# MK22FA12 register map
Vendor: Freescale Semiconductor, Inc.; Series: Kinetis_K; File version: 1.6
CPU: CM4 r0p1, little endian, no MPU, FPU, VTOR, 4 interrupt priority bits
Registers are 32-bit, read-write, reset 0x0 unless marked. A register's access mark holds for its fields unless they carry their own. Offsets are from the block's base; [hi:lo] are bit positions.

## RTC — Secure Real Time Clock
Base 0x4003D000; register names take the prefix RTC_
0x00 TSR — RTC Time Seconds Register
  [31:0] TSR — Time Seconds Register
0x04 TPR — RTC Time Prescaler Register
  [15:0] TPR — Time Prescaler Register
0x08 TAR — RTC Time Alarm Register
  [31:0] TAR — Time Alarm Register
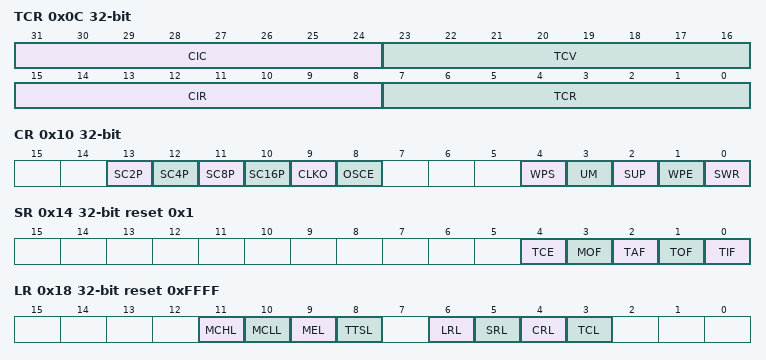
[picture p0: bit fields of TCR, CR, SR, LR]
0x0C TCR — RTC Time Compensation Register
  [31:24] CIC ro — Compensation Interval Counter
  [23:16] TCV ro — Time Compensation Value
  [15:8] CIR — Compensation Interval Register
  [7:0] TCR — Time Compensation Register
    128=Time Prescaler Register overflows every 32896 clock cycles; 255=Time Prescaler Register overflows every 32769 clock cycles; 0=Time Prescaler Register overflows every 32768 clock cycles; 1=Time Prescaler Register overflows every 32767 clock cycles; 127=Time Prescaler Register overflows every 32641 clock cycles
0x10 CR — RTC Control Register
  [13] SC2P — Oscillator 2pF Load Configure
    0=Disable the load; 1=Enable the additional load
  [12] SC4P — Oscillator 4pF Load Configure
    0=Disable the load; 1=Enable the additional load
  [11] SC8P — Oscillator 8pF Load Configure
    0=Disable the load; 1=Enable the additional load
  [10] SC16P — Oscillator 16pF Load Configure
    0=Disable the load; 1=Enable the additional load
  [9] CLKO — Clock Output
    0=The 32 kHz clock is output to other peripherals; 1=The 32 kHz clock is not output to other peripherals
  [8] OSCE — Oscillator Enable
    0=32.768 kHz oscillator is disabled; 1=32.768 kHz oscillator is enabled. After setting this bit, wait the oscillator startup time before enabling the time counter to allow the 32.768 kHz clock time to stabilize.
  [4] WPS — Wakeup Pin Select
    0=Wakeup pin asserts (active low, open drain) if the RTC interrupt asserts or the wakeup pin is turned on; 1=Wakeup pin instead outputs the RTC 32kHz clock, provided the wakeup pin is turned on and the 32kHz clock is output to other peripherals
  [3] UM — Update Mode
    0=Registers cannot be written when locked; 1=Registers can be written when locked under limited conditions
  [2] SUP — Supervisor Access
    0=Non-supervisor mode write accesses are not supported and generate a bus error; 1=Non-supervisor mode write accesses are supported
  [1] WPE — Wakeup Pin Enable
    0=Wakeup pin is disabled; 1=Wakeup pin is enabled and wakeup pin asserts if the RTC interrupt asserts or the wakeup pin is turned on
  [0] SWR — Software Reset
    0=No effect; 1=Resets all RTC registers except for the SWR bit and the RTC_WAR and RTC_RAR registers . The SWR bit is cleared by VBAT POR and by software explicitly clearing it.
0x14 SR reset 0x1 — RTC Status Register
  [4] TCE — Time Counter Enable
    0=Time counter is disabled; 1=Time counter is enabled
  [3] MOF ro — Monotonic Overflow Flag
    0=Monotonic counter overflow has not occurred; 1=Monotonic counter overflow has occurred and monotonic counter is read as zero
  [2] TAF ro — Time Alarm Flag
    0=Time alarm has not occurred; 1=Time alarm has occurred
  [1] TOF ro — Time Overflow Flag
    0=Time overflow has not occurred; 1=Time overflow has occurred and time counter is read as zero
  [0] TIF ro — Time Invalid Flag
    0=Time is valid; 1=Time is invalid and time counter is read as zero
0x18 LR reset 0xFFFF — RTC Lock Register
  [11] MCHL — Monotonic Counter High Lock
    0=Monotonic Counter High Register is locked and writes are ignored; 1=Monotonic Counter High Register is not locked and writes complete as normal
  [10] MCLL — Monotonic Counter Low Lock
    0=Monotonic Counter Low Register is locked and writes are ignored; 1=Monotonic Counter Low Register is not locked and writes complete as normal
  [9] MEL — Monotonic Enable Lock
    0=Monotonic Enable Register is locked and writes are ignored; 1=Monotonic Enable Register is not locked and writes complete as normal
  [8] TTSL — Tamper Time Seconds Lock
    0=Tamper Time Seconds Register is locked and writes are ignored; 1=Tamper Time Seconds Register is not locked and writes complete as normal
  [6] LRL — Lock Register Lock
    0=Lock Register is locked and writes are ignored; 1=Lock Register is not locked and writes complete as normal
  [5] SRL — Status Register Lock
    0=Status Register is locked and writes are ignored; 1=Status Register is not locked and writes complete as normal
  [4] CRL — Control Register Lock
    0=Control Register is locked and writes are ignored; 1=Control Register is not locked and writes complete as normal
  [3] TCL — Time Compensation Lock
    0=Time Compensation Register is locked and writes are ignored; 1=Time Compensation Register is not locked and writes complete as normal
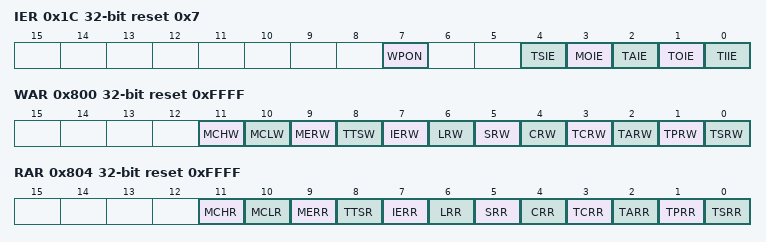
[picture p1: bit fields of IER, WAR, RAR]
0x1C IER reset 0x7 — RTC Interrupt Enable Register
  [7] WPON — Wakeup Pin On
    0=No effect; 1=If the wakeup pin is enabled, then the wakeup pin will assert
  [4] TSIE — Time Seconds Interrupt Enable
    0=Seconds interrupt is disabled; 1=Seconds interrupt is enabled
  [3] MOIE — Monotonic Overflow Interrupt Enable
    0=Monotonic overflow flag does not generate an interrupt; 1=Monotonic overflow flag does generate an interrupt
  [2] TAIE — Time Alarm Interrupt Enable
    0=Time alarm flag does not generate an interrupt; 1=Time alarm flag does generate an interrupt
  [1] TOIE — Time Overflow Interrupt Enable
    0=Time overflow flag does not generate an interrupt; 1=Time overflow flag does generate an interrupt
  [0] TIIE — Time Invalid Interrupt Enable
    0=Time invalid flag does not generate an interrupt; 1=Time invalid flag does generate an interrupt
0x20 TTSR ro reset not defined — RTC Tamper Time Seconds Register
  [31:0] TTS — Tamper Time Seconds
0x24 MER — RTC Monotonic Enable Register
  [4] MCE — Monotonic Counter Enable
    0=Writes to the monotonic counter load the counter with the value written; 1=Writes to the monotonic counter increment the counter
0x28 MCLR — RTC Monotonic Counter Low Register
  [31:0] MCL — Monotonic Counter Low
0x2C MCHR — RTC Monotonic Counter High Register
  [31:0] MCH — Monotonic Counter High
0x800 WAR reset 0xFFFF — RTC Write Access Register
  [11] MCHW — Monotonic Counter High Write
    0=Writes to the Monotonic Counter High Register are ignored; 1=Writes to the Monotonic Counter High Register complete as normal
  [10] MCLW — Monotonic Counter Low Write
    0=Writes to the Monotonic Counter Low Register are ignored; 1=Writes to the Monotonic Counter Low Register complete as normal
  [9] MERW — Monotonic Enable Register Write
    0=Writes to the Monotonic Enable Register are ignored; 1=Writes to the Monotonic Enable Register complete as normal
  [8] TTSW — Tamper Time Seconds Write
    0=Writes to the Tamper Time Seconds Register are ignored; 1=Writes to the Tamper Time Seconds Register complete as normal
  [7] IERW — Interrupt Enable Register Write
    0=Writes to the Interupt Enable Register are ignored; 1=Writes to the Interrupt Enable Register complete as normal
  [6] LRW — Lock Register Write
    0=Writes to the Lock Register are ignored; 1=Writes to the Lock Register complete as normal
  [5] SRW — Status Register Write
    0=Writes to the Status Register are ignored; 1=Writes to the Status Register complete as normal
  [4] CRW — Control Register Write
    0=Writes to the Control Register are ignored; 1=Writes to the Control Register complete as normal
  [3] TCRW — Time Compensation Register Write
    0=Writes to the Time Compensation Register are ignored; 1=Writes to the Time Compensation Register complete as normal
  [2] TARW — Time Alarm Register Write
    0=Writes to the Time Alarm Register are ignored; 1=Writes to the Time Alarm Register complete as normal
  [1] TPRW — Time Prescaler Register Write
    0=Writes to the Time Prescaler Register are ignored; 1=Writes to the Time Prescaler Register complete as normal
  [0] TSRW — Time Seconds Register Write
    0=Writes to the Time Seconds Register are ignored; 1=Writes to the Time Seconds Register complete as normal
0x804 RAR reset 0xFFFF — RTC Read Access Register
  [11] MCHR — Monotonic Counter High Read
    0=Reads to the Monotonic Counter High Register are ignored; 1=Reads to the Monotonic Counter High Register complete as normal
  [10] MCLR — Monotonic Counter Low Read
    0=Reads to the Monotonic Counter Low Register are ignored; 1=Reads to the Monotonic Counter Low Register complete as normal
  [9] MERR — Monotonic Enable Register Read
    0=Reads to the Monotonic Enable Register are ignored; 1=Reads to the Monotonic Enable Register complete as normal
  [8] TTSR — Tamper Time Seconds Read
    0=Reads to the Tamper Time Seconds Register are ignored; 1=Reads to the Tamper Time Seconds Register complete as normal
  [7] IERR — Interrupt Enable Register Read
    0=Reads to the Interrupt Enable Register are ignored; 1=Reads to the Interrupt Enable Register complete as normal
  [6] LRR — Lock Register Read
    0=Reads to the Lock Register are ignored; 1=Reads to the Lock Register complete as normal
  [5] SRR — Status Register Read
    0=Reads to the Status Register are ignored; 1=Reads to the Status Register complete as normal
  [4] CRR — Control Register Read
    0=Reads to the Control Register are ignored; 1=Reads to the Control Register complete as normal
  [3] TCRR — Time Compensation Register Read
    0=Reads to the Time Compensation Register are ignored; 1=Reads to the Time Compensation Register complete as normal
  [2] TARR — Time Alarm Register Read
    0=Reads to the Time Alarm Register are ignored; 1=Reads to the Time Alarm Register complete as normal
  [1] TPRR — Time Prescaler Register Read
    0=Reads to the Time Pprescaler Register are ignored; 1=Reads to the Time Prescaler Register complete as normal
  [0] TSRR — Time Seconds Register Read
    0=Reads to the Time Seconds Register are ignored; 1=Reads to the Time Seconds Register complete as normal
